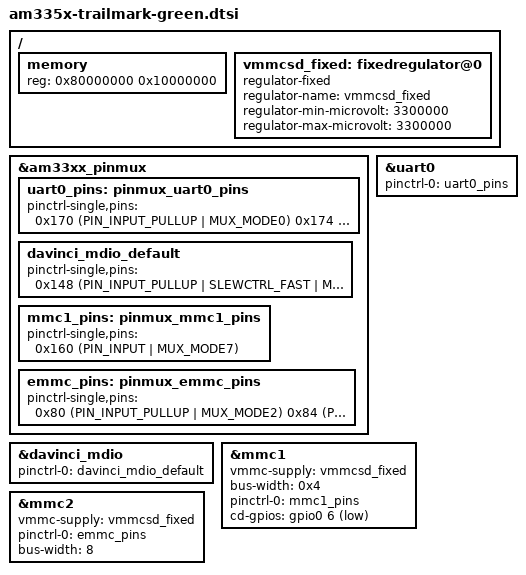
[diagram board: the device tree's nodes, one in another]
/*
 * Copyright (C) 2012 Texas Instruments Incorporated - http://www.ti.com/
 *
 * This program is free software; you can redistribute it and/or modify
 * it under the terms of the GNU General Public License version 2 as
 * published by the Free Software Foundation.
 */

/ {
	memory {
		device_type = "memory";
		reg = <0x80000000 0x10000000>; /* 256 MB */
	};
	
	vmmcsd_fixed: fixedregulator@0 {
		compatible = "regulator-fixed";
		regulator-name = "vmmcsd_fixed";
		regulator-min-microvolt = <3300000>;
		regulator-max-microvolt = <3300000>;
	};
};

&am33xx_pinmux {
	pinctrl-names = "default";

	uart0_pins: pinmux_uart0_pins {
		pinctrl-single,pins = <
			0x170 (PIN_INPUT_PULLUP | MUX_MODE0)	/* uart0_rxd.uart0_rxd */
			0x174 (PIN_OUTPUT_PULLDOWN | MUX_MODE0)	/* uart0_txd.uart0_txd */
		>;
	};

	davinci_mdio_default: davinci_mdio_default {
		pinctrl-single,pins = <
			/* MDIO */
			0x148 (PIN_INPUT_PULLUP | SLEWCTRL_FAST | MUX_MODE0)	/* mdio_data.mdio_data */
			0x14c (PIN_OUTPUT_PULLUP | MUX_MODE0)			/* mdio_clk.mdio_clk */
		>;
	};

	mmc1_pins: pinmux_mmc1_pins {
		pinctrl-single,pins = <
			0x160 (PIN_INPUT | MUX_MODE7) /* GPIO0_6 */
		>;
	};

	emmc_pins: pinmux_emmc_pins {
		pinctrl-single,pins = <
			0x80 (PIN_INPUT_PULLUP | MUX_MODE2) /* gpmc_csn1.mmc1_clk */
			0x84 (PIN_INPUT_PULLUP | MUX_MODE2) /* gpmc_csn2.mmc1_cmd */
			0x00 (PIN_INPUT_PULLUP | MUX_MODE1) /* gpmc_ad0.mmc1_dat0 */
			0x04 (PIN_INPUT_PULLUP | MUX_MODE1) /* gpmc_ad1.mmc1_dat1 */
			0x08 (PIN_INPUT_PULLUP | MUX_MODE1) /* gpmc_ad2.mmc1_dat2 */
			0x0c (PIN_INPUT_PULLUP | MUX_MODE1) /* gpmc_ad3.mmc1_dat3 */
			0x10 (PIN_INPUT_PULLUP | MUX_MODE1) /* gpmc_ad4.mmc1_dat4 */
			0x14 (PIN_INPUT_PULLUP | MUX_MODE1) /* gpmc_ad5.mmc1_dat5 */
			0x18 (PIN_INPUT_PULLUP | MUX_MODE1) /* gpmc_ad6.mmc1_dat6 */
			0x1c (PIN_INPUT_PULLUP | MUX_MODE1) /* gpmc_ad7.mmc1_dat7 */
		>;
	};
};

&uart0 {
	pinctrl-names = "default";
	pinctrl-0 = <&uart0_pins>;
	status = "okay";
};

&davinci_mdio {
	pinctrl-names = "default";
	pinctrl-0 = <&davinci_mdio_default>;
	status = "okay";
};

&mmc1 {
	vmmc-supply = <&vmmcsd_fixed>;
	status = "okay";
	bus-width = <0x4>;
	pinctrl-names = "default";
	pinctrl-0 = <&mmc1_pins>;
	cd-gpios = <&gpio0 6 GPIO_ACTIVE_LOW>;
};

&mmc2 {
	vmmc-supply = <&vmmcsd_fixed>;
	pinctrl-names = "default";
	pinctrl-0 = <&emmc_pins>;
	bus-width = <8>;
	status = "okay";
};
